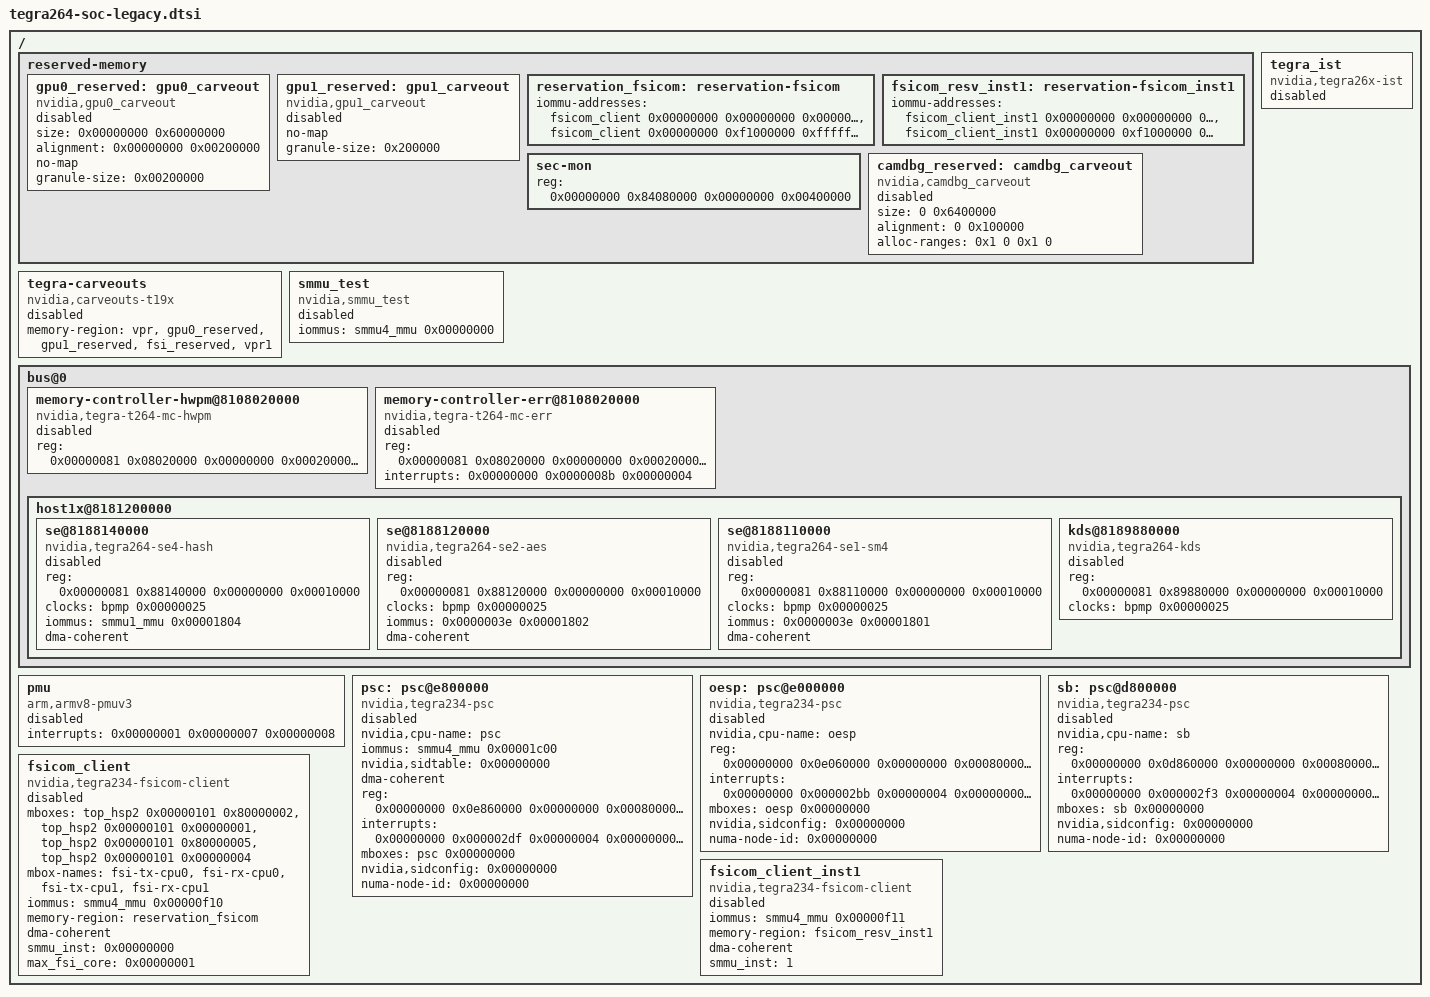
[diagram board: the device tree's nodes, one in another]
// SPDX-License-Identifier: GPL-2.0

/ {
	reserved-memory {
		gpu0_reserved: gpu0_carveout {
			compatible = "nvidia,gpu0_carveout";
			size = <0x00000000 0x60000000>;
			alignment = <0x00000000 0x00200000>;
			no-map;
			granule-size = <0x00200000>;
			status = "disabled";
		};
		gpu1_reserved: gpu1_carveout {
			compatible = "nvidia,gpu1_carveout";
			no-map;
			granule-size = <0x200000>;
			status = "disabled";
		};
		reservation_fsicom: reservation-fsicom {
			iommu-addresses = <&fsicom_client 0x00000000 0x00000000 0x00000000 0xf0000000 &fsicom_client 0x00000000 0xf1000000 0xffffffff 0x0effffff>;
		};
		fsicom_resv_inst1: reservation-fsicom_inst1 {
			iommu-addresses = <&fsicom_client_inst1 0x00000000 0x00000000 0x00000000 0xf0000000 &fsicom_client_inst1 0x00000000 0xf1000000 0xffffffff 0x0effffff>;
		};
		sec-mon {
			reg = <0x00000000 0x84080000 0x00000000 0x00400000>;
		};
		camdbg_reserved: camdbg_carveout {
			 compatible = "nvidia,camdbg_carveout";
			 size = <0 0x6400000>;
			 alignment = <0 0x100000>;
			 alloc-ranges = <0x1 0 0x1 0>;
			 status = "disabled";
		 };
	};

	tegra-carveouts {
		compatible = "nvidia,carveouts-t19x";
		memory-region = <&vpr &gpu0_reserved &gpu1_reserved &fsi_reserved &vpr1>;
		status = "disabled";
	};

	tegra_ist {
		compatible = "nvidia,tegra26x-ist";
		status = "disabled";
	};

	smmu_test {
		compatible = "nvidia,smmu_test";
		iommus = <&smmu4_mmu 0x00000000>;
		status = "disabled";
	};

	bus@0 {
		memory-controller-hwpm@8108020000 {
			compatible = "nvidia,tegra-t264-mc-hwpm";
			reg = <0x00000081 0x08020000 0x00000000 0x00020000 0x00000081 0x08040000 0x00000000 0x00020000 0x00000081 0x08060000 0x00000000 0x00020000 0x00000081 0x08080000 0x00000000 0x00020000 0x00000081 0x080a0000 0x00000000 0x00020000 0x00000081 0x080c0000 0x00000000 0x00020000 0x00000081 0x080e0000 0x00000000 0x00020000 0x00000081 0x08100000 0x00000000 0x00020000 0x00000081 0x08120000 0x00000000 0x00020000 0x00000081 0x08140000 0x00000000 0x00020000 0x00000081 0x08160000 0x00000000 0x00020000 0x00000081 0x08180000 0x00000000 0x00020000 0x00000081 0x081a0000 0x00000000 0x00020000 0x00000081 0x081c0000 0x00000000 0x00020000 0x00000081 0x081e0000 0x00000000 0x00020000 0x00000081 0x08200000 0x00000000 0x00020000 0x00000081 0x08220000 0x00000000 0x00020000>;
			status = "disabled";
		};
		memory-controller-err@8108020000 {
			compatible = "nvidia,tegra-t264-mc-err";
			reg = <0x00000081 0x08020000 0x00000000 0x00020000 0x00000081 0x08040000 0x00000000 0x00020000 0x00000081 0x08060000 0x00000000 0x00020000 0x00000081 0x08080000 0x00000000 0x00020000 0x00000081 0x080a0000 0x00000000 0x00020000 0x00000081 0x080c0000 0x00000000 0x00020000 0x00000081 0x080e0000 0x00000000 0x00020000 0x00000081 0x08100000 0x00000000 0x00020000 0x00000081 0x08120000 0x00000000 0x00020000 0x00000081 0x08140000 0x00000000 0x00020000 0x00000081 0x08160000 0x00000000 0x00020000 0x00000081 0x08180000 0x00000000 0x00020000 0x00000081 0x081a0000 0x00000000 0x00020000 0x00000081 0x081c0000 0x00000000 0x00020000 0x00000081 0x081e0000 0x00000000 0x00020000 0x00000081 0x08200000 0x00000000 0x00020000 0x00000081 0x08220000 0x00000000 0x00020000>;
			interrupts = <0x00000000 0x0000008b 0x00000004>;
			status = "disabled";
		};

		host1x@8181200000 {
			se@8188140000 {
				compatible = "nvidia,tegra264-se4-hash";
				reg = <0x00000081 0x88140000 0x00000000 0x00010000>;
				clocks = <&bpmp 0x00000025>;
				clock-names = "se";
				iommus = <&smmu1_mmu 0x00001804>;
				dma-coherent;
				status = "disabled";
			};
			se@8188120000 {
				compatible = "nvidia,tegra264-se2-aes";
				reg = <0x00000081 0x88120000 0x00000000 0x00010000>;
				clocks = <&bpmp 0x00000025>;
				clock-names = "se";
				iommus = <0x0000003e 0x00001802>;
				dma-coherent;
				status = "disabled";
			};
			se@8188110000 {
				compatible = "nvidia,tegra264-se1-sm4";
				reg = <0x00000081 0x88110000 0x00000000 0x00010000>;
				clocks = <&bpmp 0x00000025>;
				clock-names = "se";
				iommus = <0x0000003e 0x00001801>;
				dma-coherent;
				status = "disabled";
			};
			kds@8189880000 {
				compatible = "nvidia,tegra264-kds";
				reg = <0x00000081 0x89880000 0x00000000 0x00010000>;
				clocks = <&bpmp 0x00000025>;
				clock-names = "se";
				status = "disabled";
			};
		};
	};

	pmu {
		compatible = "arm,armv8-pmuv3";
		interrupts = <0x00000001 0x00000007 0x00000008>;
		status = "disabled";
	};

	psc: psc@e800000 {
		compatible = "nvidia,tegra234-psc";
		nvidia,cpu-name = "psc";
		iommus = <&smmu4_mmu 0x00001c00>;
		nvidia,sidtable = <0x00000000>;
		dma-coherent;
#mbox-cells = <0x00000001>;
		reg = <0x00000000 0x0e860000 0x00000000 0x00080000 0x00000000 0x0e80201c 0x00000000 0x00000008>;
		reg-names = "mbox-regs", "extcfg";
		interrupts = <0x00000000 0x000002df 0x00000004 0x00000000 0x000002e0 0x00000004 0x00000000 0x000002e1 0x00000004 0x00000000 0x000002e2 0x00000004 0x00000000 0x000002e3 0x00000004 0x00000000 0x000002e4 0x00000004 0x00000000 0x000002e5 0x00000004 0x00000000 0x000002e6 0x00000004>;
		mboxes = <&psc 0x00000000>;
		nvidia,sidconfig = <0x00000000>;
		numa-node-id = <0x00000000>;
		status = "disabled";
	};

	oesp: psc@e000000 {
		compatible = "nvidia,tegra234-psc";
		nvidia,cpu-name = "oesp";
		#mbox-cells = <0x00000001>;
		reg = <0x00000000 0x0e060000 0x00000000 0x00080000 0x00000000 0x0e00201c 0x00000000 0x00000008>;
		reg-names = "mbox-regs", "extcfg";
		interrupts = <0x00000000 0x000002bb 0x00000004 0x00000000 0x000002bc 0x00000004 0x00000000 0x000002bd 0x00000004 0x00000000 0x000002be 0x00000004 0x00000000 0x000002bf 0x00000004 0x00000000 0x000002c0 0x00000004 0x00000000 0x000002c1 0x00000004 0x00000000 0x000002c2 0x00000004>;
		mboxes = <&oesp 0x00000000>;
		nvidia,sidconfig = <0x00000000>;
		numa-node-id = <0x00000000>;
		phandle = <0x00000187>;
		status = "disabled";
	};

	sb: psc@d800000 {
		compatible = "nvidia,tegra234-psc";
		nvidia,cpu-name = "sb";
#mbox-cells = <0x00000001>;
		reg = <0x00000000 0x0d860000 0x00000000 0x00080000 0x00000000 0x0d80201c 0x00000000 0x00000008>;
		reg-names = "mbox-regs", "extcfg";
		interrupts = <0x00000000 0x000002f3 0x00000004 0x00000000 0x000002f4 0x00000004 0x00000000 0x000002f5 0x00000004 0x00000000 0x000002f6 0x00000004 0x00000000 0x000002f7 0x00000004 0x00000000 0x000002f8 0x00000004 0x00000000 0x000002f9 0x00000004 0x00000000 0x000002fa 0x00000004>;
		mboxes = <&sb 0x00000000>;
		nvidia,sidconfig = <0x00000000>;
		numa-node-id = <0x00000000>;
		phandle = <0x00000188>;
		status = "disabled";
	};

	fsicom_client: fsicom_client {
		compatible = "nvidia,tegra234-fsicom-client";
		mboxes = <&top_hsp2 0x00000101 0x80000002 &top_hsp2 0x00000101 0x00000001 &top_hsp2 0x00000101 0x80000005 &top_hsp2 0x00000101 0x00000004>;
		mbox-names = "fsi-tx-cpu0", "fsi-rx-cpu0", "fsi-tx-cpu1", "fsi-rx-cpu1";
		iommus = <&smmu4_mmu 0x00000f10>;
		memory-region = <&reservation_fsicom>;
		dma-coherent;
		smmu_inst = <0x00000000>;
		max_fsi_core = <0x00000001>;
		status = "disabled";
	};

        fsicom_client_inst1: fsicom_client_inst1 {
                compatible = "nvidia,tegra234-fsicom-client";
                iommus = <&smmu4_mmu 0x00000f11>;
                memory-region = <&fsicom_resv_inst1>;
                dma-coherent;
                smmu_inst = <1>;
                status = "disabled";
        };
};
